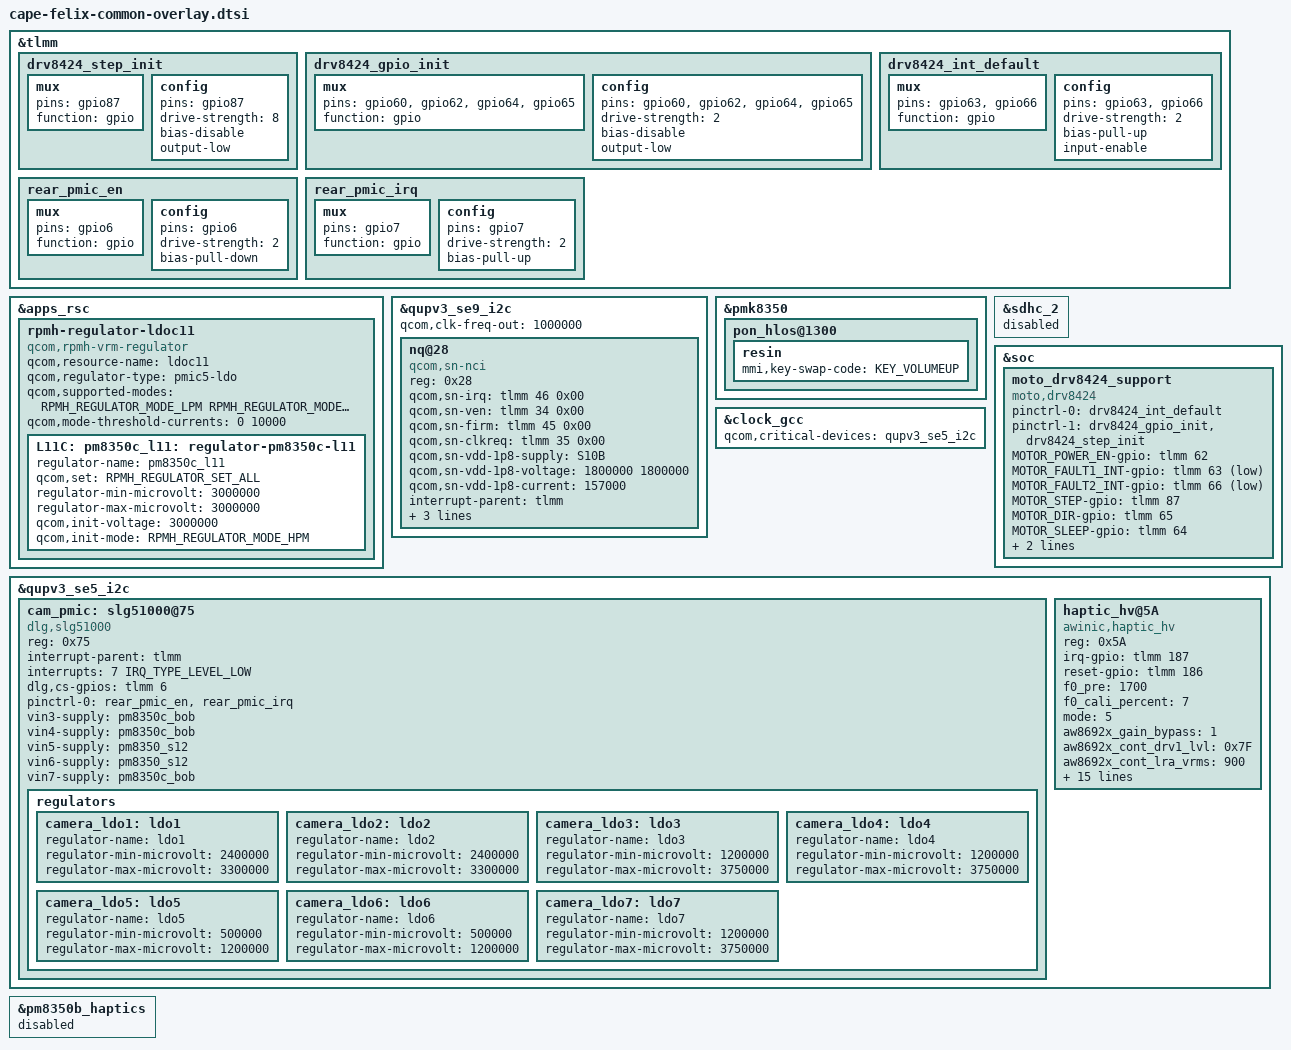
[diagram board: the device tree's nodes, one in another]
/* Copyright (c) 2022, The Linux Foundation. All rights reserved.
 *
 * This program is free software; you can redistribute it and/or modify
 * it under the terms of the GNU General Public License version 2 and
 * only version 2 as published by the Free Software Foundation.
 *
 * This program is distributed in the hope that it will be useful,
 * but WITHOUT ANY WARRANTY; without even the implied warranty of
 * MERCHANTABILITY or FITNESS FOR A PARTICULAR PURPOSE.  See the
 * GNU General Public License for more details.
 */

/*
   This base is original from "cape-mtp-pm8010-overlay.dts"
*/
#include "cape-moto-common-overlay-base.dtsi"
#include "cape-moto-common-overlay.dtsi"
#include "waipio-moto-common-charger.dtsi"
#include "cape-oneli-fingerprint.dtsi"
#include "waipio-li-charger-overlay.dtsi"
#include "cape-felix-touchscreen-overlay.dtsi"
#include "cape-oneli-thermal-overlay.dtsi"
#include <dt-bindings/regulator/qcom,rpmh-regulator-levels.h>

&tlmm {
	drv8424_step_init: drv8424_step_init {
		mux {
			pins = "gpio87";
			function = "gpio";
		};

		config {
			pins = "gpio87";
			drive-strength = <8>;
			bias-disable;
			output-low;
		};
	};

	drv8424_gpio_init: drv8424_gpio_init {
		mux {
			pins = "gpio60", "gpio62", "gpio64", "gpio65";
			function = "gpio";
		};

		config {
			pins = "gpio60", "gpio62", "gpio64", "gpio65";
			drive-strength = <2>;
			bias-disable;
			output-low;
		};
	};

	drv8424_int_default: drv8424_int_default {
		mux {
			pins = "gpio63", "gpio66";
			function = "gpio";
		};

		config {
			pins = "gpio63", "gpio66";
			drive-strength = <2>;
			bias-pull-up;
			input-enable;
		};
	};

	rear_pmic_en: rear_pmic_en {
		mux {
			pins = "gpio6";
			function = "gpio";
		};

		config {
			pins = "gpio6";
			drive-strength = <2>; /* 2 mA */
			bias-pull-down;
		};
	};

	rear_pmic_irq: rear_pmic_irq {
		mux {
			pins = "gpio7";
			function = "gpio";
		};

		config {
			pins = "gpio7";
			drive-strength = <2>; /* 2 mA */
			bias-pull-up;
		};
	};
};

&apps_rsc {
	rpmh-regulator-ldoc11 {
		compatible = "qcom,rpmh-vrm-regulator";
		qcom,resource-name = "ldoc11";
		qcom,regulator-type = "pmic5-ldo";
		qcom,supported-modes =
			<RPMH_REGULATOR_MODE_LPM
			RPMH_REGULATOR_MODE_HPM>;
		qcom,mode-threshold-currents = <0 10000>;
		L11C:
		pm8350c_l11: regulator-pm8350c-l11 {
			regulator-name = "pm8350c_l11";
			qcom,set = <RPMH_REGULATOR_SET_ALL>;
			regulator-min-microvolt = <3000000>;
			regulator-max-microvolt = <3000000>;
			qcom,init-voltage = <3000000>;
			qcom,init-mode = <RPMH_REGULATOR_MODE_HPM>;
		};
	};
};

&qupv3_se9_i2c {
        status = "ok";
        qcom,clk-freq-out = <1000000>;
        #address-cells = <1>;
        #size-cells = <0>;
        nq@28 {
                compatible = "qcom,sn-nci";
                reg = <0x28>;
                qcom,sn-irq = <&tlmm 46 0x00>;
                qcom,sn-ven = <&tlmm 34 0x00>;
                qcom,sn-firm = <&tlmm 45 0x00>;
                qcom,sn-clkreq = <&tlmm 35 0x00>;
                qcom,sn-vdd-1p8-supply = <&S10B>;
                qcom,sn-vdd-1p8-voltage = <1800000 1800000>;
                qcom,sn-vdd-1p8-current = <157000>;
                interrupt-parent = <&tlmm>;
                interrupts = <46 0>;
                interrupt-names = "nfc_irq";
                pinctrl-names = "nfc_active", "nfc_suspend";
                pinctrl-0 = <&nfc_int_active &nfc_enable_active>;
                pinctrl-1 = <&nfc_int_suspend &nfc_enable_suspend>;
        };
};

&pmk8350 {
	pon_hlos@1300 {
		resin {
			mmi,key-swap-code = <KEY_VOLUMEUP>;
		};
	};
};

&sdhc_2 {
	status = "disabled";
};

&soc {
	moto_drv8424_support {
		compatible = "moto,drv8424";
		status = "ok";
		pinctrl-names = "drv8424_int_default", "init_state";
		pinctrl-0 = <&drv8424_int_default>;
		pinctrl-1 = <&drv8424_gpio_init &drv8424_step_init>;
		MOTOR_POWER_EN-gpio = <&tlmm 62 0>;
		MOTOR_FAULT1_INT-gpio = <&tlmm 63 GPIO_ACTIVE_LOW>;
		MOTOR_FAULT2_INT-gpio = <&tlmm 66 GPIO_ACTIVE_LOW>;
		MOTOR_STEP-gpio = <&tlmm 87 0>;
		MOTOR_DIR-gpio = <&tlmm 65 0>;
		MOTOR_SLEEP-gpio = <&tlmm 64 0>;
		MOTOR_ACTIVE-gpio = <&tlmm 60 0>;
		vdd-supply = <&S10B>;
	};
};

&clock_gcc {
    qcom,critical-devices = <&qupv3_se5_i2c>;
};

&qupv3_se5_i2c {
	status = "ok";

	cam_pmic: slg51000@75 {
		compatible = "dlg,slg51000";
		reg = <0x75>;

		interrupt-parent = <&tlmm>;
		interrupts = <7 IRQ_TYPE_LEVEL_LOW>;

		dlg,cs-gpios = <&tlmm 6 0>;

		pinctrl-names = "pmic_default";
		pinctrl-0 = <&rear_pmic_en &rear_pmic_irq>;

		vin3-supply = <&pm8350c_bob>;
		vin4-supply = <&pm8350c_bob>;
		vin5-supply = <&pm8350_s12>;
		vin6-supply = <&pm8350_s12>;
		vin7-supply = <&pm8350c_bob>;

		regulators {
			camera_ldo1: ldo1 {
				regulator-name = "ldo1";
				regulator-min-microvolt = <2400000>;
				regulator-max-microvolt = <3300000>;
			};

			camera_ldo2: ldo2 {
				regulator-name = "ldo2";
				regulator-min-microvolt = <2400000>;
				regulator-max-microvolt = <3300000>;
			};

			camera_ldo3: ldo3 {
				regulator-name = "ldo3";
				regulator-min-microvolt = <1200000>;
				regulator-max-microvolt = <3750000>;
			};

			camera_ldo4: ldo4 {
				regulator-name = "ldo4";
				regulator-min-microvolt = <1200000>;
				regulator-max-microvolt = <3750000>;
			};

			camera_ldo5: ldo5 {
				regulator-name = "ldo5";
				regulator-min-microvolt = <500000>;
				regulator-max-microvolt = <1200000>;
			};

			camera_ldo6: ldo6 {
				regulator-name = "ldo6";
				regulator-min-microvolt = <500000>;
				regulator-max-microvolt = <1200000>;
			};

			camera_ldo7: ldo7 {
				regulator-name = "ldo7";
				regulator-min-microvolt = <1200000>;
				regulator-max-microvolt = <3750000>;
			};
		};
	};

	haptic_hv@5A {
		compatible = "awinic,haptic_hv";
		reg = <0x5A>;
		irq-gpio = <&tlmm 187 0>;
		reset-gpio = <&tlmm 186 0>;
		f0_pre = <1700>;
		f0_cali_percent = /bits/ 8 <7>;
		mode = /bits/ 8 <5>;
		aw8692x_gain_bypass = /bits/ 8 <1>;
		aw8692x_cont_drv1_lvl = /bits/ 8 <0x7F>;
		aw8692x_cont_lra_vrms = <900>; /* Motor rated voltage, mV */
		aw8692x_cont_drv1_time = /bits/ 8 <0x04>;
		aw8692x_cont_drv2_time = /bits/ 8 <0x0C>;
		aw8692x_cont_track_margin = /bits/ 8 <0x0F>;
		aw8692x_cont_brk_gain = /bits/ 8 <0x08>;
		aw8692x_cont_bst_brk_gain = /bits/ 8 <0x05>;
		aw8692x_cont_wait_num = /bits/ 8 <0x06>;
		aw8692x_cont_brk_time = /bits/ 8 <0x08>;
		aw8692x_brk_bst_md = /bits/ 8 <0>;
		aw8692x_cont_tset = /bits/ 8 <0x06>;
		aw8692x_cont_bemf_set = /bits/ 8 <0x02>;
		aw8692x_duration_time = /bits/ 8 <33 66 100>;
		aw8692x_d2s_gain = /bits/ 8 <0x07>;
		aw8692x_trig_config = /bits/ 8 <0 0 0 1 0 2 0 0
		                                0 0 0 1 0 2 0 0
		                                0 0 0 1 0 2 0 0>;
		aw8692x_bst_vol_default = <10500>;
	};
};

&pm8350b_haptics {
	status = "disabled";
};
